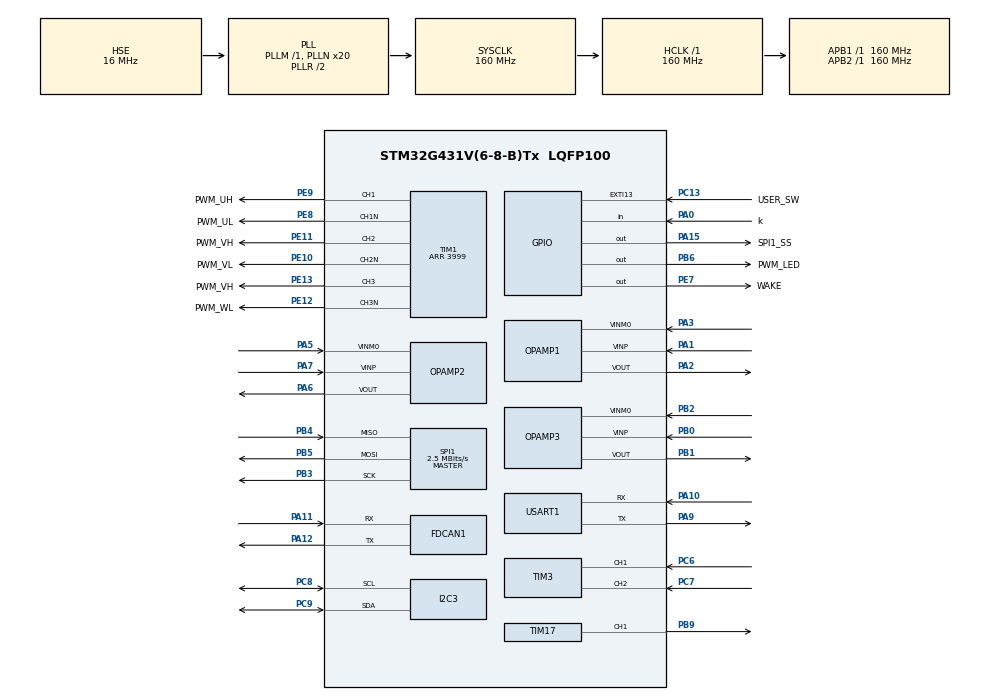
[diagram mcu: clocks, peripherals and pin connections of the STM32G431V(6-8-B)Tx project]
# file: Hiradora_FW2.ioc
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ADC1.ContinuousConvMode=ENABLE
ADC1.EOCSelection=ADC_EOC_SEQ_CONV
ADC1.EnableAnalogWatchDog1=false
ADC1.EnableInjectedConversion=ENABLE
ADC1.EnableRegularConversion=DISABLE
ADC1.ExternalTrigInjecConv=ADC_EXTERNALTRIGINJEC_T1_TRGO
ADC1.InjNumberOfConversion=3
ADC1.InjectedChannel-10\#ChannelInjectedConversion=ADC_CHANNEL_VREFINT
ADC1.InjectedChannel-6\#ChannelInjectedConversion=ADC_CHANNEL_3
ADC1.InjectedChannel-7\#ChannelInjectedConversion=ADC_CHANNEL_12
ADC1.InjectedOffsetNumber-10\#ChannelInjectedConversion=ADC_OFFSET_NONE
ADC1.InjectedOffsetNumber-6\#ChannelInjectedConversion=ADC_OFFSET_NONE
ADC1.InjectedOffsetNumber-7\#ChannelInjectedConversion=ADC_OFFSET_NONE
ADC1.InjectedRank-10\#ChannelInjectedConversion=3
ADC1.InjectedRank-6\#ChannelInjectedConversion=1
ADC1.InjectedRank-7\#ChannelInjectedConversion=2
ADC1.InjectedSamplingTime-10\#ChannelInjectedConversion=ADC_SAMPLETIME_2CYCLES_5
ADC1.InjectedSamplingTime-6\#ChannelInjectedConversion=ADC_SAMPLETIME_12CYCLES_5
ADC1.InjectedSamplingTime-7\#ChannelInjectedConversion=ADC_SAMPLETIME_12CYCLES_5
ADC1.Mode=ADC_DUALMODE_INJECSIMULT
ADC1.Rank1_Channel=ADC_CHANNEL_3
ADC1.Rank2_Channel=ADC_CHANNEL_12
ADC1.Rank3_Channel=ADC_CHANNEL_VREFINT
ADC1.master=1
ADC2.EnableInjectedConversion=ENABLE
ADC2.EnableRegularConversion=DISABLE
ADC2.InjNumberOfConversion=1
ADC2.InjectedChannel-19\#ChannelInjectedConversion=ADC_CHANNEL_3
ADC2.InjectedOffsetNumber-19\#ChannelInjectedConversion=ADC_OFFSET_NONE
ADC2.InjectedRank-19\#ChannelInjectedConversion=1
ADC2.InjectedSamplingTime-19\#ChannelInjectedConversion=ADC_SAMPLETIME_2CYCLES_5
ADC2.Mode=ADC_DUALMODE_INJECSIMULT
ADC2.Rank1_Channel=ADC_CHANNEL_3
Dma.Request0=SPI1_RX
Dma.SPI1_RX.0.Direction=DMA_PERIPH_TO_MEMORY
Dma.SPI1_RX.0.EventEnable=DISABLE
Dma.SPI1_RX.0.Instance=DMA1_Channel2
Dma.SPI1_RX.0.MemDataAlignment=DMA_MDATAALIGN_HALFWORD
Dma.SPI1_RX.0.MemInc=DMA_MINC_ENABLE
Dma.SPI1_RX.0.Mode=DMA_NORMAL
Dma.SPI1_RX.0.PeriphDataAlignment=DMA_PDATAALIGN_HALFWORD
Dma.SPI1_RX.0.PeriphInc=DMA_PINC_DISABLE
Dma.SPI1_RX.0.Polarity=HAL_DMAMUX_REQ_GEN_RISING
Dma.SPI1_RX.0.Priority=DMA_PRIORITY_VERY_HIGH
Dma.SPI1_RX.0.RequestNumber=1
Dma.SPI1_RX.0.SignalID=NONE
Dma.SPI1_RX.0.SyncEnable=DISABLE
Dma.SPI1_RX.0.SyncPolarity=HAL_DMAMUX_SYNC_NO_EVENT
Dma.SPI1_RX.0.SyncRequestNumber=1
Dma.SPI1_RX.0.SyncSignalID=NONE
FDCAN1.CalculateBaudRateNominal=1000000
FDCAN1.CalculateTimeBitNominal=1000
FDCAN1.CalculateTimeQuantumNominal=50.0
FDCAN1.DataPrescaler=2
FDCAN1.DataTimeSeg1=15
FDCAN1.DataTimeSeg2=4
FDCAN1.FrameFormat=FDCAN_FRAME_CLASSIC
FDCAN1.NominalPrescaler=8
FDCAN1.NominalTimeSeg1=15
FDCAN1.NominalTimeSeg2=4
FDCAN1.StdFiltersNbr=1
I2C3.Timing=0x30D29DE4
Mcu.Family=STM32G4
Mcu.Name=STM32G431V(6-8-B)Tx
Mcu.Package=LQFP100
NVIC.ADC1_2_IRQn=true\:0\:0\:true\:false\:true\:true\:true\:true
NVIC.DMA1_Channel2_IRQn=true\:0\:0\:false\:false\:true\:false\:true\:true
NVIC.EXTI15_10_IRQn=true\:0\:0\:false\:false\:true\:true\:true\:true
NVIC.FDCAN1_IT0_IRQn=true\:0\:0\:false\:false\:true\:true\:true\:true
NVIC.FDCAN1_IT1_IRQn=true\:0\:0\:false\:false\:true\:true\:true\:true
NVIC.PriorityGroup=NVIC_PRIORITYGROUP_4
NVIC.SPI1_IRQn=true\:0\:0\:false\:false\:true\:true\:true\:true
NVIC.TIM1_TRG_COM_TIM17_IRQn=true\:0\:0\:false\:false\:true\:true\:true\:true
NVIC.TIM1_UP_TIM16_IRQn=true\:0\:0\:true\:false\:true\:true\:true\:true
NVIC.TIM2_IRQn=true\:0\:0\:false\:false\:true\:true\:true\:true
NVIC.TIM3_IRQn=true\:0\:0\:false\:false\:true\:true\:true\:true
OPAMP1.PgaGain=OPAMP_PGA_GAIN_16_OR_MINUS_15
OPAMP1.PowerMode=OPAMP_POWERMODE_NORMALSPEED
OPAMP2.PgaGain=OPAMP_PGA_GAIN_16_OR_MINUS_15
OPAMP2.PowerMode=OPAMP_POWERMODE_NORMALSPEED
OPAMP3.PgaGain=OPAMP_PGA_GAIN_16_OR_MINUS_15
OPAMP3.PowerMode=OPAMP_POWERMODE_NORMALSPEED
PA0.GPIO_Label=k
PA0.Signal=GPIO_Input
PA1.Mode=PGA Connected-INVERTINGINPUT_IO0_BIAS
PA1.Signal=OPAMP1_VINP
PA10.Mode=Asynchronous
PA10.Signal=USART1_RX
PA11.Mode=FDCAN_Activate
PA11.Signal=FDCAN1_RX
PA12.Mode=FDCAN_Activate
PA12.Signal=FDCAN1_TX
PA15.GPIO_Label=SPI1_SS
PA15.GPIO_Speed=GPIO_SPEED_FREQ_VERY_HIGH
PA15.Signal=GPIO_Output
PA2.Signal=SharedAnalog_PA2
PA3.Mode=PGA Connected-INVERTINGINPUT_IO0_BIAS
PA3.Signal=OPAMP1_VINM0
PA5.Mode=PGA Connected-INVERTINGINPUT_IO0_BIAS
PA5.Signal=OPAMP2_VINM0
PA6.Signal=SharedAnalog_PA6
PA7.Mode=PGA Connected-INVERTINGINPUT_IO0_BIAS
PA7.Signal=OPAMP2_VINP
PA9.Mode=Asynchronous
PA9.Signal=USART1_TX
PB0.Mode=PGA Connected-INVERTINGINPUT_IO0_BIAS
PB0.Signal=OPAMP3_VINP
PB1.Signal=SharedAnalog_PB1
PB2.Mode=PGA Connected-INVERTINGINPUT_IO0_BIAS
PB2.Signal=OPAMP3_VINM0
PB3.Mode=Full_Duplex_Master
PB3.Signal=SPI1_SCK
PB4.Mode=Full_Duplex_Master
PB4.Signal=SPI1_MISO
PB5.Mode=Full_Duplex_Master
PB5.Signal=SPI1_MOSI
PB6.GPIO_Label=PWM_LED
PB6.Signal=GPIO_Output
PB9.Signal=S_TIM17_CH1
PC13.GPIO_Label=USER_SW
PC13.GPIO_ModeDefaultEXTI=GPIO_MODE_IT_FALLING
PC13.Signal=GPXTI13
PC6.Signal=S_TIM3_CH1
PC7.Signal=S_TIM3_CH2
PC8.Mode=I2C
PC8.Signal=I2C3_SCL
PC9.Mode=I2C
PC9.Signal=I2C3_SDA
PE10.GPIO_Label=PWM_VL
PE10.Mode=PWM Generation2 CH2 CH2N
PE10.Signal=TIM1_CH2N
PE11.GPIO_Label=PWM_VH
PE11.Signal=S_TIM1_CH2
PE12.GPIO_Label=PWM_WL
PE12.Mode=PWM Generation3 CH3 CH3N
PE12.Signal=TIM1_CH3N
PE13.GPIO_Label=PWM_VH
PE13.Signal=S_TIM1_CH3
PE7.GPIO_Label=WAKE
PE7.Signal=GPIO_Output
PE8.GPIO_Label=PWM_UL
PE8.Mode=PWM Generation1 CH1 CH1N
PE8.Signal=TIM1_CH1N
PE9.GPIO_Label=PWM_UH
PE9.Signal=S_TIM1_CH1
PF0-OSC_IN.Mode=HSE-External-Oscillator
PF0-OSC_IN.Signal=RCC_OSC_IN
PF1-OSC_OUT.Mode=HSE-External-Oscillator
PF1-OSC_OUT.Signal=RCC_OSC_OUT
ProjectManager.HeapSize=0x200
ProjectManager.StackSize=0xc00
ProjectManager.TargetToolchain=CMake
RCC.ADC12Freq_Value=160000000
RCC.AHBFreq_Value=160000000
RCC.APB1Freq_Value=160000000
RCC.APB1TimFreq_Value=160000000
RCC.APB2Freq_Value=160000000
RCC.APB2TimFreq_Value=160000000
RCC.CortexFreq_Value=160000000
RCC.EXTERNAL_CLOCK_VALUE=12288000
RCC.HCLKFreq_Value=160000000
RCC.HSE_VALUE=16000000
RCC.HSI48_VALUE=48000000
RCC.HSI_VALUE=16000000
RCC.LSE_VALUE=32768
RCC.PLLN=20
RCC.PLLSourceVirtual=RCC_PLLSOURCE_HSE
RCC.SYSCLKFreq_VALUE=160000000
RCC.SYSCLKSource=RCC_SYSCLKSOURCE_PLLCLK
RCC.USBFreq_Value=160000000
RCC.VCOOutputFreq_Value=320000000
SH.S_TIM17_CH1.0=TIM17_CH1,PWM Generation1 CH1
SH.S_TIM1_CH1.0=TIM1_CH1,PWM Generation1 CH1 CH1N
SH.S_TIM1_CH2.0=TIM1_CH2,PWM Generation2 CH2 CH2N
SH.S_TIM1_CH3.0=TIM1_CH3,PWM Generation3 CH3 CH3N
SH.S_TIM3_CH1.0=TIM3_CH1,Encoder_Interface
SH.S_TIM3_CH2.0=TIM3_CH2,Encoder_Interface
SH.SharedAnalog_PA2.0=OPAMP1_VOUT,PGA Connected-INVERTINGINPUT_IO0_BIAS
SH.SharedAnalog_PA2.1=ADC1_IN3,IN3-Single-Ended
SH.SharedAnalog_PA6.0=OPAMP2_VOUT,PGA Connected-INVERTINGINPUT_IO0_BIAS
SH.SharedAnalog_PA6.1=ADC2_IN3,IN3-Single-Ended
SH.SharedAnalog_PB1.0=OPAMP3_VOUT,PGA Connected-INVERTINGINPUT_IO0_BIAS
SH.SharedAnalog_PB1.1=ADC1_IN12,IN12-Single-Ended
SPI1.BaudRatePrescaler=SPI_BAUDRATEPRESCALER_64
SPI1.CLKPhase=SPI_PHASE_2EDGE
SPI1.CalculateBaudRate=2.5 MBits/s
SPI1.DataSize=SPI_DATASIZE_16BIT
SPI1.Direction=SPI_DIRECTION_2LINES
SPI1.Mode=SPI_MODE_MASTER
SPI1.VirtualType=VM_MASTER
TIM1.AutoReloadPreload=TIM_AUTORELOAD_PRELOAD_ENABLE
TIM1.Channel-PWM\ Generation1\ CH1\ CH1N=TIM_CHANNEL_1
TIM1.Channel-PWM\ Generation2\ CH2\ CH2N=TIM_CHANNEL_2
TIM1.Channel-PWM\ Generation3\ CH3\ CH3N=TIM_CHANNEL_3
TIM1.CounterMode=TIM_COUNTERMODE_CENTERALIGNED3
TIM1.DeadTime=100
TIM1.DeadTimePreload=DISABLE
TIM1.OCFastMode_PWM-PWM\ Generation1\ CH1\ CH1N=TIM_OCFAST_DISABLE
TIM1.OCFastMode_PWM-PWM\ Generation2\ CH2\ CH2N=TIM_OCFAST_DISABLE
TIM1.OCFastMode_PWM-PWM\ Generation3\ CH3\ CH3N=TIM_OCFAST_DISABLE
TIM1.OCMode_PWM-PWM\ Generation1\ CH1\ CH1N=TIM_OCMODE_PWM2
TIM1.OCMode_PWM-PWM\ Generation2\ CH2\ CH2N=TIM_OCMODE_PWM2
TIM1.OCMode_PWM-PWM\ Generation3\ CH3\ CH3N=TIM_OCMODE_PWM2
TIM1.PeriodNoDither=3999
TIM1.RepetitionCounter=1
TIM1.TIM_MasterOutputTrigger=TIM_TRGO_UPDATE
TIM16.PeriodNoDither=15999
TIM16.Prescaler=99
TIM17.Channel=TIM_CHANNEL_1
TIM17.Prescaler=159
TIM2.PeriodNoDither=199
TIM2.Prescaler=159
TIM3.EncoderMode=TIM_ENCODERMODE_TI12
TIM8.PeriodNoDither=64
USART1.VirtualMode-Asynchronous=VM_ASYNC
VP_ADC1_Vref_Input.Mode=IN-Vrefint
VP_SYS_VS_DBSignals.Mode=DisableDeadBatterySignals
VP_TIM16_VS_ClockSourceINT.Mode=Enable_Timer
VP_TIM17_VS_ClockSourceINT.Mode=Enable_Timer
VP_TIM1_VS_ClockSourceINT.Mode=Internal
VP_TIM2_VS_ClockSourceINT.Mode=Internal
VP_TIM8_VS_ClockSourceINT.Mode=Internal
VP_TIM8_VS_OPM.Mode=OPM_bit
board=custom

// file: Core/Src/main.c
/* USER CODE BEGIN Header */
/**
  ******************************************************************************
  * @file           : main.c
  * @brief          : Main program body
  ******************************************************************************
  * @attention
  *
  * Copyright (c) 2026 STMicroelectronics.
  * All rights reserved.
  *
  * This software is licensed under terms that can be found in the LICENSE file
  * in the root directory of this software component.
  * If no LICENSE file comes \with this software, it is provided AS-IS.
  *
  ******************************************************************************
  */
/* USER CODE END Header */
#include "main.h"

/* USER CODE BEGIN Includes */
#include "drive_can.h"
#include "drive_control.h"
/* USER CODE END Includes */

ADC_HandleTypeDef hadc1;
ADC_HandleTypeDef hadc2;

FDCAN_HandleTypeDef hfdcan1;

I2C_HandleTypeDef hi2c3;

OPAMP_HandleTypeDef hopamp1;
OPAMP_HandleTypeDef hopamp2;
OPAMP_HandleTypeDef hopamp3;

SPI_HandleTypeDef hspi1;
DMA_HandleTypeDef hdma_spi1_rx;

TIM_HandleTypeDef htim1;
TIM_HandleTypeDef htim2;
TIM_HandleTypeDef htim3;
TIM_HandleTypeDef htim8;
TIM_HandleTypeDef htim16;
TIM_HandleTypeDef htim17;

UART_HandleTypeDef huart1;

void SystemClock_Config(void);
static void MX_GPIO_Init(void);
static void MX_DMA_Init(void);
static void MX_TIM1_Init(void);
static void MX_FDCAN1_Init(void);
static void MX_SPI1_Init(void);
static void MX_TIM17_Init(void);
static void MX_USART1_UART_Init(void);
static void MX_I2C3_Init(void);
static void MX_TIM2_Init(void);
static void MX_TIM16_Init(void);
static void MX_ADC1_Init(void);
static void MX_ADC2_Init(void);
static void MX_OPAMP1_Init(void);
static void MX_OPAMP2_Init(void);
static void MX_OPAMP3_Init(void);
static void MX_TIM8_Init(void);
static void MX_TIM3_Init(void);

/* USER CODE BEGIN 0 */
/* printf() の出力を USART1 へ送る。 file は出力先番号（1: 標準出力、2: 標準エラー）で、この実装では共通のUARTへ送る。 ptr はデータの先頭アドレス、len は送るバイト数。 */
int _write(int file, char *ptr, int len)
{
  (void)file;
  HAL_UART_Transmit(&huart1, (uint8_t*)ptr, (uint16_t)len, HAL_MAX_DELAY);
  return len;

}
/* USER CODE END 0 */

int main(void)
{

  /* USER CODE BEGIN 1 */
  // HAL_Init() はSTM32のHALを初期化
  // SystemClock_Config()はCPUや各周辺回路に供給するクロックを設定
  // MX_..._Init() はCubeMXが生成した設定関数
  /* USER CODE END 1 */

  /* MCU Configuration--------------------------------------------------------*/

  /* Reset of all peripherals, Initializes the Flash interface and the Systick. */
  HAL_Init();

  /* Configure the system clock */
  SystemClock_Config();

  /* Initialize all configured peripherals */
  MX_GPIO_Init();
  MX_DMA_Init();
  MX_TIM1_Init();
  MX_FDCAN1_Init();
  MX_SPI1_Init();
  MX_TIM17_Init();
  MX_USART1_UART_Init();
  MX_I2C3_Init();
  MX_TIM2_Init();
  MX_TIM16_Init();
  MX_ADC1_Init();
  MX_ADC2_Init();
  MX_OPAMP1_Init();
  MX_OPAMP2_Init();
  MX_OPAMP3_Init();
  MX_TIM8_Init();
  MX_TIM3_Init();
  /* USER CODE BEGIN 2 */
  drive_init();
  /* USER CODE END 2 */

  /* Infinite loop */
  while (1) {

    /* USER CODE BEGIN 3 */
    drive_can_button_task();
    drive_report();
  }
  /* USER CODE END 3 */
}

void SystemClock_Config(void)
{
  RCC_OscInitTypeDef RCC_OscInitStruct = {0};
  RCC_ClkInitTypeDef RCC_ClkInitStruct = {0};

  /** Configure the main internal regulator output voltage
  */
  HAL_PWREx_ControlVoltageScaling(PWR_REGULATOR_VOLTAGE_SCALE1_BOOST);

  /** Initializes the RCC Oscillators according to the specified parameters
  * in the RCC_OscInitTypeDef structure.
  */
  RCC_OscInitStruct.OscillatorType = RCC_OSCILLATORTYPE_HSE;
  RCC_OscInitStruct.HSEState = RCC_HSE_ON;
  RCC_OscInitStruct.PLL.PLLState = RCC_PLL_ON;
  RCC_OscInitStruct.PLL.PLLSource = RCC_PLLSOURCE_HSE;
  RCC_OscInitStruct.PLL.PLLM = RCC_PLLM_DIV1;
  RCC_OscInitStruct.PLL.PLLN = 20;
  RCC_OscInitStruct.PLL.PLLP = RCC_PLLP_DIV2;
  RCC_OscInitStruct.PLL.PLLQ = RCC_PLLQ_DIV2;
  RCC_OscInitStruct.PLL.PLLR = RCC_PLLR_DIV2;
  if (HAL_RCC_OscConfig(&RCC_OscInitStruct) != HAL_OK)
  {
    Error_Handler();
  }

  /** Initializes the CPU, AHB and APB buses clocks
  */
  RCC_ClkInitStruct.ClockType = RCC_CLOCKTYPE_HCLK|RCC_CLOCKTYPE_SYSCLK
                              |RCC_CLOCKTYPE_PCLK1|RCC_CLOCKTYPE_PCLK2;
  RCC_ClkInitStruct.SYSCLKSource = RCC_SYSCLKSOURCE_PLLCLK;
  RCC_ClkInitStruct.AHBCLKDivider = RCC_SYSCLK_DIV1;
  RCC_ClkInitStruct.APB1CLKDivider = RCC_HCLK_DIV1;
  RCC_ClkInitStruct.APB2CLKDivider = RCC_HCLK_DIV1;

  if (HAL_RCC_ClockConfig(&RCC_ClkInitStruct, FLASH_LATENCY_4) != HAL_OK)
  {
    Error_Handler();
  }
}

static void MX_ADC1_Init(void)
{

  ADC_MultiModeTypeDef multimode = {0};
  ADC_InjectionConfTypeDef sConfigInjected = {0};

  /** Common config
  */
  hadc1.Instance = ADC1;
  hadc1.Init.ClockPrescaler = ADC_CLOCK_SYNC_PCLK_DIV4;
  hadc1.Init.Resolution = ADC_RESOLUTION_12B;
  hadc1.Init.DataAlign = ADC_DATAALIGN_RIGHT;
  hadc1.Init.GainCompensation = 0;
  hadc1.Init.ScanConvMode = ADC_SCAN_ENABLE;
  hadc1.Init.EOCSelection = ADC_EOC_SEQ_CONV;
  hadc1.Init.LowPowerAutoWait = DISABLE;
  hadc1.Init.ContinuousConvMode = ENABLE;
  hadc1.Init.NbrOfConversion = 1;
  hadc1.Init.DiscontinuousConvMode = DISABLE;
  hadc1.Init.DMAContinuousRequests = DISABLE;
  hadc1.Init.Overrun = ADC_OVR_DATA_PRESERVED;
  hadc1.Init.OversamplingMode = DISABLE;
  if (HAL_ADC_Init(&hadc1) != HAL_OK)
  {
    Error_Handler();
  }

  /** Configure the ADC multi-mode
  */
  multimode.Mode = ADC_DUALMODE_INJECSIMULT;
  multimode.DMAAccessMode = ADC_DMAACCESSMODE_DISABLED;
  multimode.TwoSamplingDelay = ADC_TWOSAMPLINGDELAY_1CYCLE;
  if (HAL_ADCEx_MultiModeConfigChannel(&hadc1, &multimode) != HAL_OK)
  {
    Error_Handler();
  }

  /** Configure Injected Channel
  */
  sConfigInjected.InjectedChannel = ADC_CHANNEL_3;
  sConfigInjected.InjectedRank = ADC_INJECTED_RANK_1;
  sConfigInjected.InjectedSamplingTime = ADC_SAMPLETIME_12CYCLES_5;
  sConfigInjected.InjectedSingleDiff = ADC_SINGLE_ENDED;
  sConfigInjected.InjectedOffsetNumber = ADC_OFFSET_NONE;
  sConfigInjected.InjectedOffset = 0;
  sConfigInjected.InjectedNbrOfConversion = 3;
  sConfigInjected.InjectedDiscontinuousConvMode = DISABLE;
  sConfigInjected.AutoInjectedConv = DISABLE;
  sConfigInjected.QueueInjectedContext = DISABLE;
  sConfigInjected.ExternalTrigInjecConv = ADC_EXTERNALTRIGINJEC_T1_TRGO;
  sConfigInjected.ExternalTrigInjecConvEdge = ADC_EXTERNALTRIGINJECCONV_EDGE_RISING;
  sConfigInjected.InjecOversamplingMode = DISABLE;
  if (HAL_ADCEx_InjectedConfigChannel(&hadc1, &sConfigInjected) != HAL_OK)
  {
    Error_Handler();
  }

  /** Configure Injected Channel
  */
  sConfigInjected.InjectedChannel = ADC_CHANNEL_12;
  sConfigInjected.InjectedRank = ADC_INJECTED_RANK_2;
  if (HAL_ADCEx_InjectedConfigChannel(&hadc1, &sConfigInjected) != HAL_OK)
  {
    Error_Handler();
  }

  /** Configure Injected Channel
  */
  sConfigInjected.InjectedChannel = ADC_CHANNEL_VREFINT;
  sConfigInjected.InjectedRank = ADC_INJECTED_RANK_3;
  sConfigInjected.InjectedSamplingTime = ADC_SAMPLETIME_2CYCLES_5;
  if (HAL_ADCEx_InjectedConfigChannel(&hadc1, &sConfigInjected) != HAL_OK)
  {
    Error_Handler();
  }

}

static void MX_ADC2_Init(void)
{

  ADC_InjectionConfTypeDef sConfigInjected = {0};

  /** Common config
  */
  hadc2.Instance = ADC2;
  hadc2.Init.ClockPrescaler = ADC_CLOCK_SYNC_PCLK_DIV4;
  hadc2.Init.Resolution = ADC_RESOLUTION_12B;
  hadc2.Init.DataAlign = ADC_DATAALIGN_RIGHT;
  hadc2.Init.GainCompensation = 0;
  hadc2.Init.ScanConvMode = ADC_SCAN_DISABLE;
  hadc2.Init.EOCSelection = ADC_EOC_SINGLE_CONV;
  hadc2.Init.LowPowerAutoWait = DISABLE;
  hadc2.Init.ContinuousConvMode = ENABLE;
  hadc2.Init.NbrOfConversion = 1;
  hadc2.Init.DiscontinuousConvMode = DISABLE;
  hadc2.Init.DMAContinuousRequests = DISABLE;
  hadc2.Init.Overrun = ADC_OVR_DATA_PRESERVED;
  hadc2.Init.OversamplingMode = DISABLE;
  if (HAL_ADC_Init(&hadc2) != HAL_OK)
  {
    Error_Handler();
  }

  /** Configure Injected Channel
  */
  sConfigInjected.InjectedChannel = ADC_CHANNEL_3;
  sConfigInjected.InjectedRank = ADC_INJECTED_RANK_1;
  sConfigInjected.InjectedSamplingTime = ADC_SAMPLETIME_2CYCLES_5;
  sConfigInjected.InjectedSingleDiff = ADC_SINGLE_ENDED;
  sConfigInjected.InjectedOffsetNumber = ADC_OFFSET_NONE;
  sConfigInjected.InjectedOffset = 0;
  sConfigInjected.InjectedNbrOfConversion = 1;
  sConfigInjected.InjectedDiscontinuousConvMode = DISABLE;
  sConfigInjected.AutoInjectedConv = DISABLE;
  sConfigInjected.QueueInjectedContext = DISABLE;
  sConfigInjected.InjecOversamplingMode = DISABLE;
  if (HAL_ADCEx_InjectedConfigChannel(&hadc2, &sConfigInjected) != HAL_OK)
  {
    Error_Handler();
  }

}

static void MX_FDCAN1_Init(void)
{

  hfdcan1.Instance = FDCAN1;
  hfdcan1.Init.ClockDivider = FDCAN_CLOCK_DIV1;
  hfdcan1.Init.FrameFormat = FDCAN_FRAME_CLASSIC;
  hfdcan1.Init.Mode = FDCAN_MODE_NORMAL;
  hfdcan1.Init.AutoRetransmission = DISABLE;
  hfdcan1.Init.TransmitPause = DISABLE;
  hfdcan1.Init.ProtocolException = DISABLE;
  hfdcan1.Init.NominalPrescaler = 8;
  hfdcan1.Init.NominalSyncJumpWidth = 1;
  hfdcan1.Init.NominalTimeSeg1 = 15;
  hfdcan1.Init.NominalTimeSeg2 = 4;
  hfdcan1.Init.DataPrescaler = 2;
  hfdcan1.Init.DataSyncJumpWidth = 1;
  hfdcan1.Init.DataTimeSeg1 = 15;
  hfdcan1.Init.DataTimeSeg2 = 4;
  hfdcan1.Init.StdFiltersNbr = 1;
  hfdcan1.Init.ExtFiltersNbr = 0;
  hfdcan1.Init.TxFifoQueueMode = FDCAN_TX_FIFO_OPERATION;
  if (HAL_FDCAN_Init(&hfdcan1) != HAL_OK)
  {
    Error_Handler();
  }
  /* USER CODE BEGIN FDCAN1_Init 2 */
  FDCAN1_ConfigFilterAndStart();
  /* USER CODE END FDCAN1_Init 2 */

}

static void MX_I2C3_Init(void)
{

  hi2c3.Instance = I2C3;
  hi2c3.Init.Timing = 0x30D29DE4;
  hi2c3.Init.OwnAddress1 = 0;
  hi2c3.Init.AddressingMode = I2C_ADDRESSINGMODE_7BIT;
  hi2c3.Init.DualAddressMode = I2C_DUALADDRESS_DISABLE;
  hi2c3.Init.OwnAddress2 = 0;
  hi2c3.Init.OwnAddress2Masks = I2C_OA2_NOMASK;
  hi2c3.Init.GeneralCallMode = I2C_GENERALCALL_DISABLE;
  hi2c3.Init.NoStretchMode = I2C_NOSTRETCH_DISABLE;
  if (HAL_I2C_Init(&hi2c3) != HAL_OK)
  {
    Error_Handler();
  }

  /** Configure Analogue filter
  */
  if (HAL_I2CEx_ConfigAnalogFilter(&hi2c3, I2C_ANALOGFILTER_ENABLE) != HAL_OK)
  {
    Error_Handler();
  }

  /** Configure Digital filter
  */
  if (HAL_I2CEx_ConfigDigitalFilter(&hi2c3, 0) != HAL_OK)
  {
    Error_Handler();
  }

}

static void MX_OPAMP1_Init(void)
{

  hopamp1.Instance = OPAMP1;
  hopamp1.Init.PowerMode = OPAMP_POWERMODE_NORMALSPEED;
  hopamp1.Init.Mode = OPAMP_PGA_MODE;
  hopamp1.Init.NonInvertingInput = OPAMP_NONINVERTINGINPUT_IO0;
  hopamp1.Init.InternalOutput = DISABLE;
  hopamp1.Init.TimerControlledMuxmode = OPAMP_TIMERCONTROLLEDMUXMODE_DISABLE;
  hopamp1.Init.PgaConnect = OPAMP_PGA_CONNECT_INVERTINGINPUT_IO0_BIAS;
  hopamp1.Init.PgaGain = OPAMP_PGA_GAIN_16_OR_MINUS_15;
  hopamp1.Init.UserTrimming = OPAMP_TRIMMING_FACTORY;
  if (HAL_OPAMP_Init(&hopamp1) != HAL_OK)
  {
    Error_Handler();
  }

}

static void MX_OPAMP2_Init(void)
{

  hopamp2.Instance = OPAMP2;
  hopamp2.Init.PowerMode = OPAMP_POWERMODE_NORMALSPEED;
  hopamp2.Init.Mode = OPAMP_PGA_MODE;
  hopamp2.Init.NonInvertingInput = OPAMP_NONINVERTINGINPUT_IO0;
  hopamp2.Init.InternalOutput = DISABLE;
  hopamp2.Init.TimerControlledMuxmode = OPAMP_TIMERCONTROLLEDMUXMODE_DISABLE;
  hopamp2.Init.PgaConnect = OPAMP_PGA_CONNECT_INVERTINGINPUT_IO0_BIAS;
  hopamp2.Init.PgaGain = OPAMP_PGA_GAIN_16_OR_MINUS_15;
  hopamp2.Init.UserTrimming = OPAMP_TRIMMING_FACTORY;
  if (HAL_OPAMP_Init(&hopamp2) != HAL_OK)
  {
    Error_Handler();
  }

}

static void MX_OPAMP3_Init(void)
{

  hopamp3.Instance = OPAMP3;
  hopamp3.Init.PowerMode = OPAMP_POWERMODE_NORMALSPEED;
  hopamp3.Init.Mode = OPAMP_PGA_MODE;
  hopamp3.Init.NonInvertingInput = OPAMP_NONINVERTINGINPUT_IO0;
  hopamp3.Init.InternalOutput = DISABLE;
  hopamp3.Init.TimerControlledMuxmode = OPAMP_TIMERCONTROLLEDMUXMODE_DISABLE;
  hopamp3.Init.PgaConnect = OPAMP_PGA_CONNECT_INVERTINGINPUT_IO0_BIAS;
  hopamp3.Init.PgaGain = OPAMP_PGA_GAIN_16_OR_MINUS_15;
  hopamp3.Init.UserTrimming = OPAMP_TRIMMING_FACTORY;
  if (HAL_OPAMP_Init(&hopamp3) != HAL_OK)
  {
    Error_Handler();
  }

}

static void MX_SPI1_Init(void)
{

  /* SPI1 parameter configuration*/
  hspi1.Instance = SPI1;
  hspi1.Init.Mode = SPI_MODE_MASTER;
  hspi1.Init.Direction = SPI_DIRECTION_2LINES;
  hspi1.Init.DataSize = SPI_DATASIZE_16BIT;
  hspi1.Init.CLKPolarity = SPI_POLARITY_LOW;
  hspi1.Init.CLKPhase = SPI_PHASE_2EDGE;
  hspi1.Init.NSS = SPI_NSS_SOFT;
  hspi1.Init.BaudRatePrescaler = SPI_BAUDRATEPRESCALER_64;
  hspi1.Init.FirstBit = SPI_FIRSTBIT_MSB;
  hspi1.Init.TIMode = SPI_TIMODE_DISABLE;
  hspi1.Init.CRCCalculation = SPI_CRCCALCULATION_DISABLE;
  hspi1.Init.CRCPolynomial = 7;
  hspi1.Init.CRCLength = SPI_CRC_LENGTH_DATASIZE;
  hspi1.Init.NSSPMode = SPI_NSS_PULSE_DISABLE;
  if (HAL_SPI_Init(&hspi1) != HAL_OK)
  {
    Error_Handler();
  }

}

static void MX_TIM1_Init(void)
{

  TIM_ClockConfigTypeDef sClockSourceConfig = {0};
  TIM_MasterConfigTypeDef sMasterConfig = {0};
  TIM_OC_InitTypeDef sConfigOC = {0};
  TIM_BreakDeadTimeConfigTypeDef sBreakDeadTimeConfig = {0};

  htim1.Instance = TIM1;
  htim1.Init.Prescaler = 0;
  htim1.Init.CounterMode = TIM_COUNTERMODE_CENTERALIGNED3;
  htim1.Init.Period = 3999;
  htim1.Init.ClockDivision = TIM_CLOCKDIVISION_DIV1;
  htim1.Init.RepetitionCounter = 1;
  htim1.Init.AutoReloadPreload = TIM_AUTORELOAD_PRELOAD_ENABLE;
  if (HAL_TIM_Base_Init(&htim1) != HAL_OK)
  {
    Error_Handler();
  }
  sClockSourceConfig.ClockSource = TIM_CLOCKSOURCE_INTERNAL;
  if (HAL_TIM_ConfigClockSource(&htim1, &sClockSourceConfig) != HAL_OK)
  {
    Error_Handler();
  }
  if (HAL_TIM_PWM_Init(&htim1) != HAL_OK)
  {
    Error_Handler();
  }
  sMasterConfig.MasterOutputTrigger = TIM_TRGO_UPDATE;
  sMasterConfig.MasterOutputTrigger2 = TIM_TRGO2_RESET;
  sMasterConfig.MasterSlaveMode = TIM_MASTERSLAVEMODE_DISABLE;
  if (HAL_TIMEx_MasterConfigSynchronization(&htim1, &sMasterConfig) != HAL_OK)
  {
    Error_Handler();
  }
  sConfigOC.OCMode = TIM_OCMODE_PWM2;
  sConfigOC.Pulse = 0;
  sConfigOC.OCPolarity = TIM_OCPOLARITY_HIGH;
  sConfigOC.OCNPolarity = TIM_OCNPOLARITY_HIGH;
  sConfigOC.OCFastMode = TIM_OCFAST_DISABLE;
  sConfigOC.OCIdleState = TIM_OCIDLESTATE_RESET;
  sConfigOC.OCNIdleState = TIM_OCNIDLESTATE_RESET;
  if (HAL_TIM_PWM_ConfigChannel(&htim1, &sConfigOC, TIM_CHANNEL_1) != HAL_OK)
  {
    Error_Handler();
  }
  if (HAL_TIM_PWM_ConfigChannel(&htim1, &sConfigOC, TIM_CHANNEL_2) != HAL_OK)
  {
    Error_Handler();
  }
  if (HAL_TIM_PWM_ConfigChannel(&htim1, &sConfigOC, TIM_CHANNEL_3) != HAL_OK)
  {
    Error_Handler();
  }
  sBreakDeadTimeConfig.OffStateRunMode = TIM_OSSR_DISABLE;
  sBreakDeadTimeConfig.OffStateIDLEMode = TIM_OSSI_DISABLE;
  sBreakDeadTimeConfig.LockLevel = TIM_LOCKLEVEL_OFF;
  sBreakDeadTimeConfig.DeadTime = 100;
  sBreakDeadTimeConfig.BreakState = TIM_BREAK_DISABLE;
  sBreakDeadTimeConfig.BreakPolarity = TIM_BREAKPOLARITY_HIGH;
  sBreakDeadTimeConfig.BreakFilter = 0;
  sBreakDeadTimeConfig.BreakAFMode = TIM_BREAK_AFMODE_INPUT;
  sBreakDeadTimeConfig.Break2State = TIM_BREAK2_DISABLE;
  sBreakDeadTimeConfig.Break2Polarity = TIM_BREAK2POLARITY_HIGH;
  sBreakDeadTimeConfig.Break2Filter = 0;
  sBreakDeadTimeConfig.Break2AFMode = TIM_BREAK_AFMODE_INPUT;
  sBreakDeadTimeConfig.AutomaticOutput = TIM_AUTOMATICOUTPUT_DISABLE;
  if (HAL_TIMEx_ConfigBreakDeadTime(&htim1, &sBreakDeadTimeConfig) != HAL_OK)
  {
    Error_Handler();
  }
  HAL_TIM_MspPostInit(&htim1);

}

static void MX_TIM2_Init(void)
{

  TIM_ClockConfigTypeDef sClockSourceConfig = {0};
  TIM_MasterConfigTypeDef sMasterConfig = {0};

  htim2.Instance = TIM2;
  htim2.Init.Prescaler = 159;
  htim2.Init.CounterMode = TIM_COUNTERMODE_UP;
  htim2.Init.Period = 199;
  htim2.Init.ClockDivision = TIM_CLOCKDIVISION_DIV1;
  htim2.Init.AutoReloadPreload = TIM_AUTORELOAD_PRELOAD_DISABLE;
  if (HAL_TIM_Base_Init(&htim2) != HAL_OK)
  {
    Error_Handler();
  }
  sClockSourceConfig.ClockSource = TIM_CLOCKSOURCE_INTERNAL;
  if (HAL_TIM_ConfigClockSource(&htim2, &sClockSourceConfig) != HAL_OK)
  {
    Error_Handler();
  }
  sMasterConfig.MasterOutputTrigger = TIM_TRGO_RESET;
  sMasterConfig.MasterSlaveMode = TIM_MASTERSLAVEMODE_DISABLE;
  if (HAL_TIMEx_MasterConfigSynchronization(&htim2, &sMasterConfig) != HAL_OK)
  {
    Error_Handler();
  }

}

static void MX_TIM3_Init(void)
{

  TIM_Encoder_InitTypeDef sConfig = {0};
  TIM_MasterConfigTypeDef sMasterConfig = {0};

  htim3.Instance = TIM3;
  htim3.Init.Prescaler = 0;
  htim3.Init.CounterMode = TIM_COUNTERMODE_UP;
  htim3.Init.Period = 65535;
  htim3.Init.ClockDivision = TIM_CLOCKDIVISION_DIV1;
  htim3.Init.AutoReloadPreload = TIM_AUTORELOAD_PRELOAD_DISABLE;
  sConfig.EncoderMode = TIM_ENCODERMODE_TI12;
  sConfig.IC1Polarity = TIM_ICPOLARITY_RISING;
  sConfig.IC1Selection = TIM_ICSELECTION_DIRECTTI;
  sConfig.IC1Prescaler = TIM_ICPSC_DIV1;
  sConfig.IC1Filter = 0;
  sConfig.IC2Polarity = TIM_ICPOLARITY_RISING;
  sConfig.IC2Selection = TIM_ICSELECTION_DIRECTTI;
  sConfig.IC2Prescaler = TIM_ICPSC_DIV1;
  sConfig.IC2Filter = 0;
  if (HAL_TIM_Encoder_Init(&htim3, &sConfig) != HAL_OK)
  {
    Error_Handler();
  }
  sMasterConfig.MasterOutputTrigger = TIM_TRGO_RESET;
  sMasterConfig.MasterSlaveMode = TIM_MASTERSLAVEMODE_DISABLE;
  if (HAL_TIMEx_MasterConfigSynchronization(&htim3, &sMasterConfig) != HAL_OK)
  {
    Error_Handler();
  }

}

static void MX_TIM8_Init(void)
{

  TIM_ClockConfigTypeDef sClockSourceConfig = {0};
  TIM_MasterConfigTypeDef sMasterConfig = {0};

  htim8.Instance = TIM8;
  htim8.Init.Prescaler = 0;
  htim8.Init.CounterMode = TIM_COUNTERMODE_UP;
  htim8.Init.Period = 64;
  htim8.Init.ClockDivision = TIM_CLOCKDIVISION_DIV1;
  htim8.Init.RepetitionCounter = 0;
  htim8.Init.AutoReloadPreload = TIM_AUTORELOAD_PRELOAD_DISABLE;
  if (HAL_TIM_Base_Init(&htim8) != HAL_OK)
  {
    Error_Handler();
  }
  sClockSourceConfig.ClockSource = TIM_CLOCKSOURCE_INTERNAL;
  if (HAL_TIM_ConfigClockSource(&htim8, &sClockSourceConfig) != HAL_OK)
  {
    Error_Handler();
  }
  if (HAL_TIM_OnePulse_Init(&htim8, TIM_OPMODE_SINGLE) != HAL_OK)
  {
    Error_Handler();
  }
  sMasterConfig.MasterOutputTrigger = TIM_TRGO_RESET;
  sMasterConfig.MasterOutputTrigger2 = TIM_TRGO2_RESET;
  sMasterConfig.MasterSlaveMode = TIM_MASTERSLAVEMODE_DISABLE;
  if (HAL_TIMEx_MasterConfigSynchronization(&htim8, &sMasterConfig) != HAL_OK)
  {
    Error_Handler();
  }

}

static void MX_TIM16_Init(void)
{

  htim16.Instance = TIM16;
  htim16.Init.Prescaler = 99;
  htim16.Init.CounterMode = TIM_COUNTERMODE_UP;
  htim16.Init.Period = 15999;
  htim16.Init.ClockDivision = TIM_CLOCKDIVISION_DIV1;
  htim16.Init.RepetitionCounter = 0;
  htim16.Init.AutoReloadPreload = TIM_AUTORELOAD_PRELOAD_DISABLE;
  if (HAL_TIM_Base_Init(&htim16) != HAL_OK)
  {
    Error_Handler();
  }

}

static void MX_TIM17_Init(void)
{

  TIM_OC_InitTypeDef sConfigOC = {0};
  TIM_BreakDeadTimeConfigTypeDef sBreakDeadTimeConfig = {0};

  htim17.Instance = TIM17;
  htim17.Init.Prescaler = 159;
  htim17.Init.CounterMode = TIM_COUNTERMODE_UP;
  htim17.Init.Period = 65535;
  htim17.Init.ClockDivision = TIM_CLOCKDIVISION_DIV1;
  htim17.Init.RepetitionCounter = 0;
  htim17.Init.AutoReloadPreload = TIM_AUTORELOAD_PRELOAD_DISABLE;
  if (HAL_TIM_Base_Init(&htim17) != HAL_OK)
  {
    Error_Handler();
  }
  if (HAL_TIM_PWM_Init(&htim17) != HAL_OK)
  {
    Error_Handler();
  }
  sConfigOC.OCMode = TIM_OCMODE_PWM1;
  sConfigOC.Pulse = 0;
  sConfigOC.OCPolarity = TIM_OCPOLARITY_HIGH;
  sConfigOC.OCNPolarity = TIM_OCNPOLARITY_HIGH;
  sConfigOC.OCFastMode = TIM_OCFAST_DISABLE;
  sConfigOC.OCIdleState = TIM_OCIDLESTATE_RESET;
  sConfigOC.OCNIdleState = TIM_OCNIDLESTATE_RESET;
  if (HAL_TIM_PWM_ConfigChannel(&htim17, &sConfigOC, TIM_CHANNEL_1) != HAL_OK)
  {
    Error_Handler();
  }
  sBreakDeadTimeConfig.OffStateRunMode = TIM_OSSR_DISABLE;
  sBreakDeadTimeConfig.OffStateIDLEMode = TIM_OSSI_DISABLE;
  sBreakDeadTimeConfig.LockLevel = TIM_LOCKLEVEL_OFF;
  sBreakDeadTimeConfig.DeadTime = 0;
  sBreakDeadTimeConfig.BreakState = TIM_BREAK_DISABLE;
  sBreakDeadTimeConfig.BreakPolarity = TIM_BREAKPOLARITY_HIGH;
  sBreakDeadTimeConfig.BreakFilter = 0;
  sBreakDeadTimeConfig.AutomaticOutput = TIM_AUTOMATICOUTPUT_DISABLE;
  if (HAL_TIMEx_ConfigBreakDeadTime(&htim17, &sBreakDeadTimeConfig) != HAL_OK)
  {
    Error_Handler();
  }
  HAL_TIM_MspPostInit(&htim17);

}

static void MX_USART1_UART_Init(void)
{

  huart1.Instance = USART1;
  huart1.Init.BaudRate = 115200;
  huart1.Init.WordLength = UART_WORDLENGTH_8B;
  huart1.Init.StopBits = UART_STOPBITS_1;
  huart1.Init.Parity = UART_PARITY_NONE;
  huart1.Init.Mode = UART_MODE_TX_RX;
  huart1.Init.HwFlowCtl = UART_HWCONTROL_NONE;
  huart1.Init.OverSampling = UART_OVERSAMPLING_16;
  huart1.Init.OneBitSampling = UART_ONE_BIT_SAMPLE_DISABLE;
  huart1.Init.ClockPrescaler = UART_PRESCALER_DIV1;
  huart1.AdvancedInit.AdvFeatureInit = UART_ADVFEATURE_NO_INIT;
  if (HAL_UART_Init(&huart1) != HAL_OK)
  {
    Error_Handler();
  }
  if (HAL_UARTEx_SetTxFifoThreshold(&huart1, UART_TXFIFO_THRESHOLD_1_8) != HAL_OK)
  {
    Error_Handler();
  }
  if (HAL_UARTEx_SetRxFifoThreshold(&huart1, UART_RXFIFO_THRESHOLD_1_8) != HAL_OK)
  {
    Error_Handler();
  }
  if (HAL_UARTEx_DisableFifoMode(&huart1) != HAL_OK)
  {
    Error_Handler();
  }

}

static void MX_DMA_Init(void)
{

  /* DMA controller clock enable */
  __HAL_RCC_DMAMUX1_CLK_ENABLE();
  __HAL_RCC_DMA1_CLK_ENABLE();

  /* DMA interrupt init */
  /* DMA1_Channel2_IRQn interrupt configuration */
  HAL_NVIC_SetPriority(DMA1_Channel2_IRQn, 0, 0);
  HAL_NVIC_EnableIRQ(DMA1_Channel2_IRQn);

}

static void MX_GPIO_Init(void)
{
  GPIO_InitTypeDef GPIO_InitStruct = {0};

  /* GPIO Ports Clock Enable */
  __HAL_RCC_GPIOC_CLK_ENABLE();
  __HAL_RCC_GPIOF_CLK_ENABLE();
  __HAL_RCC_GPIOA_CLK_ENABLE();
  __HAL_RCC_GPIOB_CLK_ENABLE();
  __HAL_RCC_GPIOE_CLK_ENABLE();

  /*Configure GPIO pin Output Level */
  HAL_GPIO_WritePin(WAKE_GPIO_Port, WAKE_Pin, GPIO_PIN_RESET);

  /*Configure GPIO pin Output Level */
  HAL_GPIO_WritePin(SPI1_SS_GPIO_Port, SPI1_SS_Pin, GPIO_PIN_RESET);

  /*Configure GPIO pin Output Level */
  HAL_GPIO_WritePin(PWM_LED_GPIO_Port, PWM_LED_Pin, GPIO_PIN_RESET);

  /*Configure GPIO pin : USER_SW_Pin */
  GPIO_InitStruct.Pin = USER_SW_Pin;
  GPIO_InitStruct.Mode = GPIO_MODE_IT_FALLING;
  GPIO_InitStruct.Pull = GPIO_NOPULL;
  HAL_GPIO_Init(USER_SW_GPIO_Port, &GPIO_InitStruct);

  /*Configure GPIO pin : k_Pin */
  GPIO_InitStruct.Pin = k_Pin;
  GPIO_InitStruct.Mode = GPIO_MODE_INPUT;
  GPIO_InitStruct.Pull = GPIO_NOPULL;
  HAL_GPIO_Init(k_GPIO_Port, &GPIO_InitStruct);

  /*Configure GPIO pin : WAKE_Pin */
  GPIO_InitStruct.Pin = WAKE_Pin;
  GPIO_InitStruct.Mode = GPIO_MODE_OUTPUT_PP;
  GPIO_InitStruct.Pull = GPIO_NOPULL;
  GPIO_InitStruct.Speed = GPIO_SPEED_FREQ_LOW;
  HAL_GPIO_Init(WAKE_GPIO_Port, &GPIO_InitStruct);

  /*Configure GPIO pin : SPI1_SS_Pin */
  GPIO_InitStruct.Pin = SPI1_SS_Pin;
  GPIO_InitStruct.Mode = GPIO_MODE_OUTPUT_PP;
  GPIO_InitStruct.Pull = GPIO_NOPULL;
  GPIO_InitStruct.Speed = GPIO_SPEED_FREQ_VERY_HIGH;
  HAL_GPIO_Init(SPI1_SS_GPIO_Port, &GPIO_InitStruct);

  /*Configure GPIO pin : PWM_LED_Pin */
  GPIO_InitStruct.Pin = PWM_LED_Pin;
  GPIO_InitStruct.Mode = GPIO_MODE_OUTPUT_PP;
  GPIO_InitStruct.Pull = GPIO_NOPULL;
  GPIO_InitStruct.Speed = GPIO_SPEED_FREQ_LOW;
  HAL_GPIO_Init(PWM_LED_GPIO_Port, &GPIO_InitStruct);

  /* EXTI interrupt init */
  HAL_NVIC_SetPriority(EXTI15_10_IRQn, 0, 0);
  HAL_NVIC_EnableIRQ(EXTI15_10_IRQn);

}

void Error_Handler(void)
{
  __disable_irq();
  while (1)
  {
  }
}
